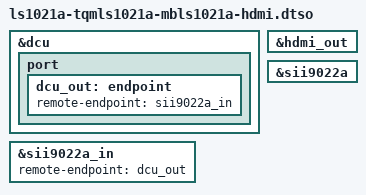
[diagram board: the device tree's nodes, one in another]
// SPDX-License-Identifier: (GPL-2.0-or-later OR MIT)
/*
 * Copyright 2013-2014 Freescale Semiconductor, Inc.
 * Copyright 2018-2025 TQ-Systems GmbH <linux@ew.tq-group.com>,
 * D-82229 Seefeld, Germany.
 * Author: Alexander Stein
 */

/dts-v1/;
/plugin/;

&dcu {
	status = "okay";

	port {
		dcu_out: endpoint {
			remote-endpoint = <&sii9022a_in>;
		};
	};
};

&hdmi_out {
	status = "okay";
};

&sii9022a {
	status = "okay";
};

&sii9022a_in {
	remote-endpoint = <&dcu_out>;
};
